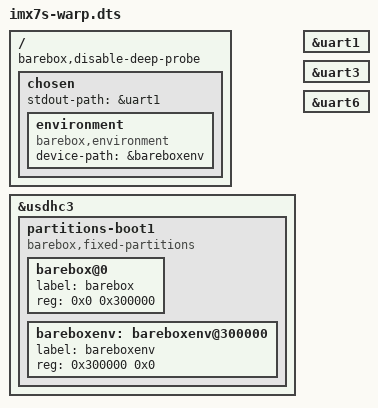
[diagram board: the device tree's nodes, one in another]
/*
 * The code contained herein is licensed under the GNU General Public
 * License. You may obtain a copy of the GNU General Public License
 * Version 2 or later at the following locations:
 *
 * http://www.opensource.org/licenses/gpl-license.html
 * http://www.gnu.org/copyleft/gpl.html
 */

#include <arm/nxp/imx/imx7s-warp.dts>

/ {
	barebox,disable-deep-probe;

	chosen {
		stdout-path = &uart1;

		environment {
			compatible = "barebox,environment";
			device-path = &bareboxenv;
		};
	};
};

&usdhc3 {
	partitions-boot1 {
		compatible = "barebox,fixed-partitions";
		#address-cells = <1>;
		#size-cells = <1>;

		barebox@0 {
			label = "barebox";
			reg = <0x0 0x300000>;
		};

		bareboxenv: bareboxenv@300000 {
			label = "bareboxenv";
			reg = <0x300000 0x0>;
		};
	};
};

/* FIXME: barebox serial is broken when barebox applies requested reparenting */
&uart1 {
	/delete-property/ assigned-clocks;
	/delete-property/ assigned-clock-parents;
};

&uart3  {
	/delete-property/ assigned-clocks;
	/delete-property/ assigned-clock-parents;
};

&uart6 {
	/delete-property/ assigned-clocks;
	/delete-property/ assigned-clock-parents;
};
